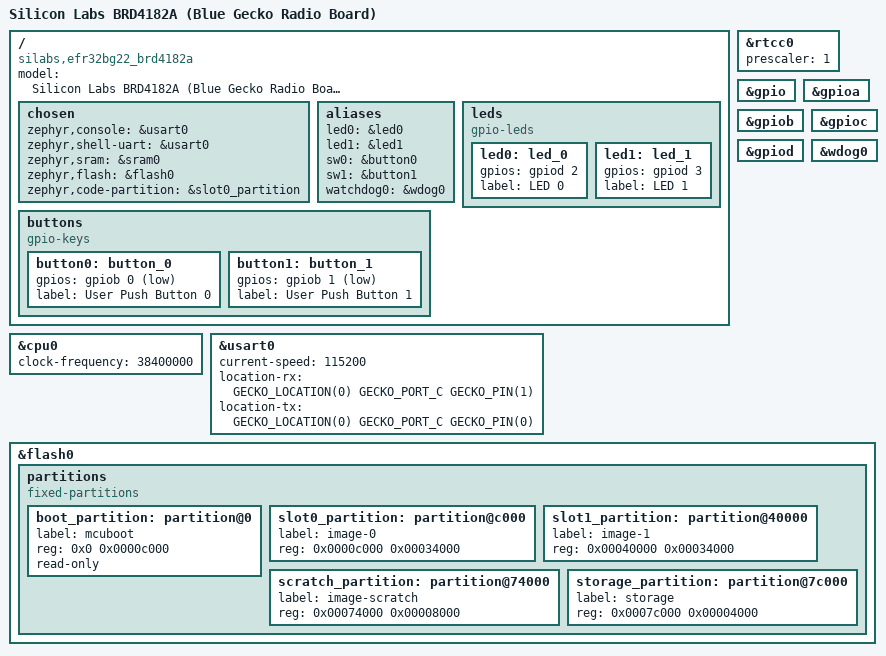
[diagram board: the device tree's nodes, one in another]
/*
 * Copyright (c) 2020 Cargomon Systems GmbH
 *
 * SPDX-License-Identifier: Apache-2.0
 */

/dts-v1/;
#include <silabs/efr32bg22c224f512im40.dtsi>

/ {
	model = "Silicon Labs BRD4182A (Blue Gecko Radio Board)";
	compatible = "silabs,efr32bg22_brd4182a", "silabs,efr32bg22";

	chosen {
		zephyr,console = &usart0;
		zephyr,shell-uart = &usart0;
		zephyr,sram = &sram0;
		zephyr,flash = &flash0;
		zephyr,code-partition = &slot0_partition;
	};

	/* These aliases are provided for compatibility with samples */
	aliases {
		led0 = &led0;
		led1 = &led1;
		sw0 = &button0;
		sw1 = &button1;
		watchdog0 = &wdog0;
	};

	leds {
		compatible = "gpio-leds";
		led0: led_0 {
			gpios = <&gpiod 2 0>;
			label = "LED 0";
		};
		led1: led_1 {
			gpios = <&gpiod 3 0>;
			label = "LED 1";
		};
	};

	buttons {
		compatible = "gpio-keys";
		button0: button_0 {
			/* gpio flags need validation */
			gpios = <&gpiob 0 GPIO_ACTIVE_LOW>;
			label = "User Push Button 0";
		};
		button1: button_1 {
			/* gpio flags need validation */
			gpios = <&gpiob 1 GPIO_ACTIVE_LOW>;
			label = "User Push Button 1";
		};
	};

};

&cpu0 {
	clock-frequency = <38400000>;
};

&usart0 {
	current-speed = <115200>;
	location-rx = <GECKO_LOCATION(0) GECKO_PORT_C GECKO_PIN(1)>;
	location-tx = <GECKO_LOCATION(0) GECKO_PORT_C GECKO_PIN(0)>;
	status = "okay";
};

&rtcc0 {
	prescaler = <1>;
	status = "okay";
};

&gpio {
	status = "okay";
};

&gpioa {
	status = "okay";
};

&gpiob {
	status = "okay";
};

&gpioc {
	status = "okay";
};

&gpiod {
	status = "okay";
};

&wdog0 {
	status = "okay";
};

&flash0 {
	/*
	 * If the chosen node has no zephyr,code-partition property, the
	 * application image link uses the entire flash device. If a
	 * zephyr,code-partition property is defined, the application link
	 * will be restricted to that partition.
	 *
	 * For more information, see:
	 * http://docs.zephyrproject.org/latest/guides/dts/index.html#flash-partitions
	 */
	partitions {
		compatible = "fixed-partitions";
		#address-cells = <1>;
		#size-cells = <1>;

		/* Reserve 48 kB for the bootloader */
		boot_partition: partition@0 {
			label = "mcuboot";
			reg = <0x0 0x0000c000>;
			read-only;
		};

		/* Reserve 208 kB for the application in slot 0 */
		slot0_partition: partition@c000 {
			label = "image-0";
			reg = <0x0000c000 0x00034000>;
		};

		/* Reserve 208 kB for the application in slot 1 */
		slot1_partition: partition@40000 {
			label = "image-1";
			reg = <0x00040000 0x00034000>;
		};

		/* Reserve 32 kB for the scratch partition */
		scratch_partition: partition@74000 {
			label = "image-scratch";
			reg = <0x00074000 0x00008000>;
		};

		/* Set 16Kb of storage at the end of the 512Kb of flash */
		storage_partition: partition@7c000 {
			label = "storage";
			reg = <0x0007c000 0x00004000>;
		};

	};
};
